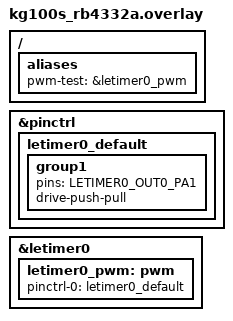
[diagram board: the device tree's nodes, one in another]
/*
 * Copyright (c) 2026 Martin Moya <martin.moya@focus.uy>
 *
 * SPDX-License-Identifier: Apache-2.0
 */

#include <zephyr/dt-bindings/pwm/pwm.h>
#include <zephyr/dt-bindings/pinctrl/silabs/xg21-pinctrl.h>

/ {
	aliases {
		pwm-test = &letimer0_pwm;
	};
};

&pinctrl {
	letimer0_default: letimer0_default {
		group1 {
			pins = <LETIMER0_OUT0_PA1>;
			drive-push-pull;
		};
	};
};

&letimer0 {
	status = "okay";

	letimer0_pwm: pwm {
		pinctrl-0 = <&letimer0_default>;
		pinctrl-names = "default";
		status = "okay";
	};
};
